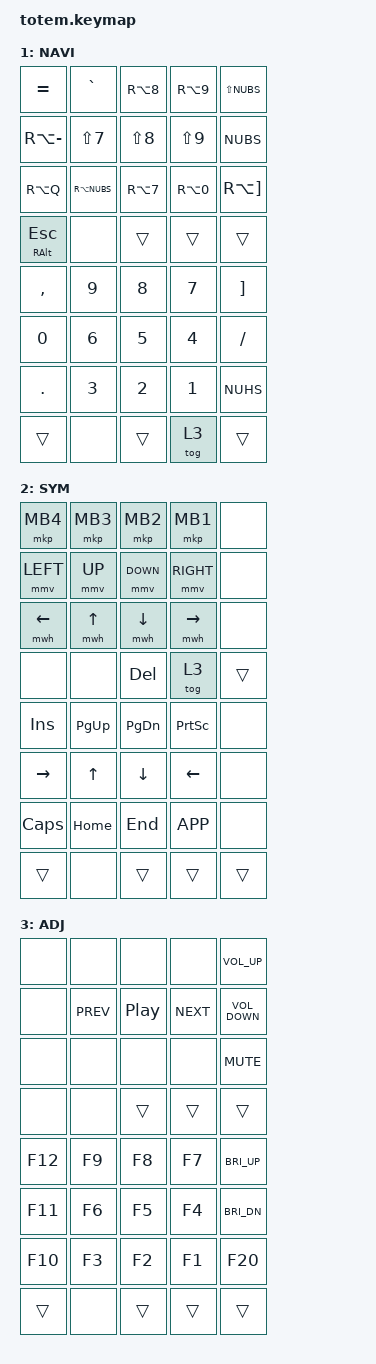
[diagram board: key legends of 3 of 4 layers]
//
//                                                        ▀▀▀▀▀     ▀▀▀▀▀          ▀▀█▀▀
//                                                        ▄▀▀▀▄  ▄  ▄▀▀▀▄  ▄  ▄▀▀▀▄  █  ▄▀▀▀▄
//                                                        █   █  █  █   █  █  █   █  █  █   █
//                                                         ▀▀▀   █   ▀▀▀   █   ▀▀▀   ▀   ▀▀▀
//                                                               █      ▄▄▄█▄▄▄    █   █
//                                                               ▀      █  █  █     █▄█
//                                                             ▀▀▀▀▀    █  █  █      ▀
//                                                                      ▀  ▀  ▀
//
// ▄▄▄▄▄▄▄▄▄▄▄▄▄▄▄▄▄▄▄▄▄▄▄▄▄▄▄▄▄▄▄▄▄▄▄▄▄▄▄▄▄▄▄▄▄▄▄▄▄▄▄▄▄▄▄▄▄▄▄▄▄▄▄▄▄▄▄▄▄▄▄▄▄▄▄▄▄▄▄▄▄▄▄▄▄▄▄▄▄▄▄▄▄▄▄▄▄▄▄▄▄▄▄▄▄▄▄▄▄▄▄▄▄▄▄▄▄▄▄▄▄▄▄▄▄▄▄▄▄▄▄▄▄▄▄▄▄▄▄▄▄▄▄▄▄▄▄▄▄


#include <behaviors.dtsi>
#include <dt-bindings/zmk/keys.h>
#include <dt-bindings/zmk/bt.h>
#include <dt-bindings/zmk/outputs.h>

#define BASE 0
#define NAV  1
#define SYM  2
#define ADJ  3

&mt {
  quick-tap-ms = <100>;
  global-quick-tap;
  flavor = "tap-preferred";
  tapping-term-ms = <170>;
};

/ {
    // combos {
    //         compatible = "zmk,combos";
    //         combo_esc {
    //             timeout-ms = <50>;
    //             key-positions = <0 1>;
    //             bindings = <&kp ESC>;
    //         };
    // };
combos {
        compatible = "zmk,combos";

        combo0 {
            timeout-ms = <40>;
            key-positions = <10 11 12 13>;
            bindings = <&kp LC(LALT)>;
        };

        combo1 {
            timeout-ms = <40>;
            key-positions = <33 32 31 30>;
            bindings = <&kp LC(LALT)>;
        };

        combo2 {
            timeout-ms = <40>;
            key-positions = <11 12 13>;
            bindings = <&kp LA(LGUI)>;
        };

        combo3 {
            timeout-ms = <40>;
            key-positions = <32 31 30>;
            bindings = <&kp LA(LGUI)>;
        };

        combo4 {
            timeout-ms = <40>;
            key-positions = <11 12 13>;
            bindings = <&kp LC(LGUI)>;
        };

        combo5 {
            timeout-ms = <40>;
            key-positions = <32 31 30>;
            bindings = <&kp LC(LGUI)>;
        };

        combo6 {
            timeout-ms = <40>;
            key-positions = <5 7 8 6>;
            bindings = <&kp LC(C)>;
        };

        combo7 {
            timeout-ms = <40>;
            key-positions = <28 27 26 25>;
            bindings = <&kp LC(C)>;
        };

        combo8 {
            timeout-ms = <40>;
            key-positions = <0 1 2 3>;
            bindings = <&kp ESC>;
        };

        combo9 {
            timeout-ms = <40>;
            key-positions = <23 22 21 20>;
            bindings = <&kp ESC>;
        };

        combo10 {
            timeout-ms = <40>;
            key-positions = <12 13 19>;
            bindings = <&kp LC(LSHIFT)>;
        };

        combo11 {
            timeout-ms = <40>;
            key-positions = <33 32 19>;
            bindings = <&none>;
        };

        combo12 {
            timeout-ms = <40>;
            key-positions = <11 12>;
            bindings = <&kp LALT>;
        };

        combo13 {
            timeout-ms = <40>;
            key-positions = <32 31>;
            bindings = <&kp LALT>;
        };

        combo14 {
            timeout-ms = <40>;
            key-positions = <11 12>;
            bindings = <&kp LGUI>;
        };

        combo15 {
            timeout-ms = <40>;
            key-positions = <32 31>;
            bindings = <&kp LGUI>;
        };

        combo16 {
            timeout-ms = <40>;
            key-positions = <12 13>;
            bindings = <&kp LCTRL>;
        };

        combo17 {
            timeout-ms = <40>;
            key-positions = <33 32>;
            bindings = <&kp LCTRL>;
        };

        combo18 {
            timeout-ms = <40>;
            key-positions = <11 31>;
            bindings = <&kp TAB>;
        };

        combo19 {
            timeout-ms = <40>;
            key-positions = <10 30>;
            bindings = <&kp ESC>;
        };

        combo20 {
            timeout-ms = <40>;
            key-positions = <0 0>;
            bindings = <&kp LCTRL>;
        };

        combo21 {
            timeout-ms = <40>;
            key-positions = <0 0>;
            bindings = <&kp LCTRL>;
        };

        combo22 {
            timeout-ms = <40>;
            key-positions = <0 0 0>;
            bindings = <&kp LC(LGUI)>;
        };

        combo23 {
            timeout-ms = <40>;
            key-positions = <0 0 0>;
            bindings = <&kp LA(LGUI)>;
        };

        combo24 {
            timeout-ms = <40>;
            key-positions = <0 0>;
            bindings = <&kp LGUI>;
        };

        combo25 {
            timeout-ms = <40>;
            key-positions = <0 0 0 0>;
            bindings = <&kp LC(LALT)>;
        };

        combo26 {
            timeout-ms = <40>;
            key-positions = <33 32 19>;
            bindings = <&kp LC(LSHIFT)>;
        };

        combo27 {
            timeout-ms = <40>;
            key-positions = <11 12 13 19>;
            bindings = <&kp LC(LSHIFT)>;
        };
    };

    macros {
        gif: gif {
            label = "giphy";
            compatible = "zmk,behavior-macro";
            #binding-cells = <0>;
            bindings
                = <&macro_press &kp LSHFT>
                , <&macro_tap &kp N2>
                , <&macro_release &kp LSHFT>
                , <&macro_tap &kp G &kp I &kp F>
                ;
        };
    };

        keymap {
                compatible = "zmk,keymap";
// ▄▄▄▄▄▄▄▄▄▄▄▄▄▄▄▄▄▄▄▄▄▄▄▄▄▄▄▄▄▄▄▄▄▄▄▄▄▄▄▄▄▄▄▄▄▄▄▄▄▄▄▄▄▄▄▄▄▄▄▄▄▄▄▄▄▄▄▄▄▄▄▄▄▄▄▄▄▄▄▄▄▄▄▄▄▄▄▄▄▄▄▄▄▄▄▄▄▄▄▄▄▄▄▄▄▄▄▄▄▄▄▄▄▄▄▄▄▄▄▄▄▄▄▄▄▄▄▄▄▄▄▄▄▄▄▄▄▄▄▄▄▄▄▄▄▄▄▄▄

                base_layer {
// ┏━━━━━━━━━━━━━━━━━━━━━━━━━━━━━━━━━━━━━━━┓
label= "BASE"                              ;
// ┗━━━━━━━━━━━━━━━━━━━━━━━━━━━━━━━━━━━━━━━┛
//             ┏━━━━━━━━━━━┳━━━━━━━━━━━┳━━━━━━━━━━━┳━━━━━━━━━━━┳━━━━━━━━━━━┓   ┏━━━━━━━━━━━┳━━━━━━━━━━━┳━━━━━━━━━━━┳━━━━━━━━━━━┳━━━━━━━━━━━┓
//             ┃     Q     ┃     W     ┃     F     ┃     P     ┃     G     ┃   ┃     J     ┃     L     ┃     U     ┃     Y     ┃     ;     ┃
//             ┣━━━━━━━━━━━╋━━━━━━━━━━━╋━━━━━━━━━━━╋━━━━━━━━━━━╋━━━━━━━━━━━┫   ┣━━━━━━━━━━━╋━━━━━━━━━━━╋━━━━━━━━━━━╋━━━━━━━━━━━╋━━━━━━━━━━━┫
//             ┃     A     ┃     R     ┃     S     ┃     T     ┃     D     ┃   ┃     H     ┃     N     ┃     E     ┃     I     ┃     O     ┃
// ┏━━━━━━━━━━━╋━━━━━━━━━━━╋━━━━━━━━━━━╋━━━━━━━━━━━╋━━━━━━━━━━━╋━━━━━━━━━━━┫   ┣━━━━━━━━━━━╋━━━━━━━━━━━╋━━━━━━━━━━━╋━━━━━━━━━━━╋━━━━━━━━━━━╋━━━━━━━━━━━┓
// ┃           ┃     Z     ┃     X     ┃     C     ┃     V     ┃     B     ┃   ┃     K     ┃     M     ┃     ,     ┃     .     ┃     /     ┃           ┃
// ┗━━━━━━━━━━━┻━━━━━━━━━━━┻━━━━━━━━━━━╋━━━━━━━━━━━╋━━━━━━━━━━━╋━━━━━━━━━━━┫   ┣━━━━━━━━━━━╋━━━━━━━━━━━╋━━━━━━━━━━━╋━━━━━━━━━━━┻━━━━━━━━━━━┻━━━━━━━━━━━┛
//                                     ┃           ┃    TAB    ┃    SPC    ┃   ┃   ENTER   ┃   BSPC    ┃           ┃
//                                     ┗━━━━━━━━━━━┻━━━━━━━━━━━┻━━━━━━━━━━━┛   ┗━━━━━━━━━━━┻━━━━━━━━━━━┻━━━━━━━━━━━┛
//  bindings = <
// // ╷           ╷           ╷           ╷           ╷           ╷           ╷   ╷           ╷           ╷           ╷           ╷           ╷           ╷
//
//                 &kp Q       &kp W       &kp F       &kp P       &kp G           &kp J       &kp L       &kp U       &kp Y       &kp SEMI
//                 &mt LGUI A  &mt LALT R  &mt LCTRL S &mt LSHFT T &kp D           &kp H       &mt RSHFT N &mt RCTRL E &mt RALT I  &mt RGUI O
//     &kp Z       &kp Z       &kp X       &kp C       &kp V       &kp B           &kp K       &kp M       &kp COMMA   &kp DOT     &kp FSLH    &kp FSLH
//                                         &kp TAB     &kp TAB     &lt NAV SPACE   &lt SYM RET &kp BSPC    &kp BSPC
//                         >;
bindings = <
            &kp Z &kp Y &kp U    &kp A  &kp Q     &kp P  &kp B  &kp M  &kp L  &kp SQT
            &kp C &kp S &kp I    &kp E  &kp O     &kp D  &kp T  &kp N  &kp R  &kp H
    &kp TAB &kp V &kp X &kp LBKT &kp SEMI &kp RBKT &kp W &kp G &kp F &kp J &kp K &kp DOT
                     &kp BSPC &tog 1 &kp LSHIFT &kp SPACE &tog 2 &kp ENTER
>;
                };

// ▄▄▄▄▄▄▄▄▄▄▄▄▄▄▄▄▄▄▄▄▄▄▄▄▄▄▄▄▄▄▄▄▄▄▄▄▄▄▄▄▄▄▄▄▄▄▄▄▄▄▄▄▄▄▄▄▄▄▄▄▄▄▄▄▄▄▄▄▄▄▄▄▄▄▄▄▄▄▄▄▄▄▄▄▄▄▄▄▄▄▄▄▄▄▄▄▄▄▄▄▄▄▄▄▄▄▄▄▄▄▄▄▄▄▄▄▄▄▄▄▄▄▄▄▄▄▄▄▄▄▄▄▄▄▄▄▄▄▄▄▄▄▄▄▄▄▄▄▄


                nav_layer {
// ┏━━━━━━━━━━━━━━━━━━━━━━━━━━━━━━━━━━━━━━━┓
label= "NAVI"                              ;
// ┗━━━━━━━━━━━━━━━━━━━━━━━━━━━━━━━━━━━━━━━┛
//             ┏━━━━━━━━━━━┳━━━━━━━━━━━┳━━━━━━━━━━━┳━━━━━━━━━━━┳━━━━━━━━━━━┓   ┏━━━━━━━━━━━┳━━━━━━━━━━━┳━━━━━━━━━━━┳━━━━━━━━━━━┳━━━━━━━━━━━┓
//             ┃           ┃           ┃     UP    ┃           ┃     {     ┃   ┃     }     ┃     7     ┃     8     ┃     9     ┃     +     ┃
//             ┣━━━━━━━━━━━╋━━━━━━━━━━━╋━━━━━━━━━━━╋━━━━━━━━━━━╋━━━━━━━━━━━┫   ┣━━━━━━━━━━━╋━━━━━━━━━━━╋━━━━━━━━━━━╋━━━━━━━━━━━╋━━━━━━━━━━━┫
//             ┃   SHIFT   ┃   LEFT    ┃    DOWN   ┃   RIGHT   ┃     [     ┃   ┃     ]     ┃     4     ┃     5     ┃     6     ┃     -     ┃
// ┏━━━━━━━━━━━╋━━━━━━━━━━━╋━━━━━━━━━━━╋━━━━━━━━━━━╋━━━━━━━━━━━╋━━━━━━━━━━━┫   ┣━━━━━━━━━━━╋━━━━━━━━━━━╋━━━━━━━━━━━╋━━━━━━━━━━━╋━━━━━━━━━━━╋━━━━━━━━━━━┓
// ┃           ┃           ┃   P UP    ┃  C LOCK   ┃  P DOWN   ┃     (     ┃   ┃     )     ┃     1     ┃     2     ┃     3     ┃     *     ┃           ┃
// ┗━━━━━━━━━━━┻━━━━━━━━━━━┻━━━━━━━━━━━╋━━━━━━━━━━━╋━━━━━━━━━━━╋━━━━━━━━━━━┫   ┣━━━━━━━━━━━╋━━━━━━━━━━━╋━━━━━━━━━━━╋━━━━━━━━━━━┻━━━━━━━━━━━┻━━━━━━━━━━━┛
//                                     ┃           ┃    TAB    ┃    SPC    ┃   ┃    DEL    ┃     0     ┃           ┃
//                                     ┗━━━━━━━━━━━┻━━━━━━━━━━━┻━━━━━━━━━━━┛   ┗━━━━━━━━━━━┻━━━━━━━━━━━┻━━━━━━━━━━━┛
//  bindings = <
// // ╷           ╷           ╷           ╷           ╷           ╷           ╷   ╷           ╷           ╷           ╷           ╷           ╷           ╷
//
//                 &kp ESC     &bt BT_CLR  &kp UP      &kp EQUAL   &kp LBRC        &kp RBRC    &kp KP_N7   &kp KP_N8   &kp KP_N9   &kp KP_PLUS
//                 &kp LSHFT   &kp LEFT    &kp DOWN    &kp RIGHT   &kp LBKT        &kp RBKT    &kp KP_N4   &kp KP_N5   &kp KP_N6   &kp KP_MINUS
//     &trans      &kp DEL     &kp PG_UP   &kp CAPS    &kp PG_DN   &kp LPAR        &kp RPAR    &kp KP_N1   &kp KP_N2   &kp KP_N3   &kp KP_MULTIPLY &trans
//                                         &trans      &trans      &trans          &mo ADJ     &kp KP_N0   &trans
//                         >;
   bindings = <
                &kp EQUAL &kp GRAVE &kp RA(8) &kp RA(9) &kp LS(NUBS)
                &kp RA(MINUS) &kp LS(7) &kp LS(8) &kp LS(9) &kp NUBS
                &kp RA(Q) &kp RA(NUBS) &kp RA(7) &kp RA(0) &kp RA(RBKT)
                &mt RALT ESC &none &trans &trans &trans
                &kp COMMA &kp 9 &kp 8 &kp 7 &kp RBKT
                &kp 0 &kp 6 &kp 5 &kp 4 &kp SLASH
                &kp DOT &kp 3 &kp 2 &kp 1 &kp NUHS
                &trans &none &trans &tog 3 &trans
            >;
                };

// ▄▄▄▄▄▄▄▄▄▄▄▄▄▄▄▄▄▄▄▄▄▄▄▄▄▄▄▄▄▄▄▄▄▄▄▄▄▄▄▄▄▄▄▄▄▄▄▄▄▄▄▄▄▄▄▄▄▄▄▄▄▄▄▄▄▄▄▄▄▄▄▄▄▄▄▄▄▄▄▄▄▄▄▄▄▄▄▄▄▄▄▄▄▄▄▄▄▄▄▄▄▄▄▄▄▄▄▄▄▄▄▄▄▄▄▄▄▄▄▄▄▄▄▄▄▄▄▄▄▄▄▄▄▄▄▄▄▄▄▄▄▄▄▄▄▄▄▄▄


                sim_layer {
// ┏━━━━━━━━━━━━━━━━━━━━━━━━━━━━━━━━━━━━━━━┓
label= "SYM"                               ;
// ┗━━━━━━━━━━━━━━━━━━━━━━━━━━━━━━━━━━━━━━━┛
//             ┏━━━━━━━━━━━┳━━━━━━━━━━━┳━━━━━━━━━━━┳━━━━━━━━━━━┳━━━━━━━━━━━┓   ┏━━━━━━━━━━━┳━━━━━━━━━━━┳━━━━━━━━━━━┳━━━━━━━━━━━┳━━━━━━━━━━━┓
//             ┃     !     ┃     @     ┃     #     ┃     $     ┃     %     ┃   ┃     ˆ     ┃     &     ┃     Ü     ┃     '     ┃     "     ┃
//             ┣━━━━━━━━━━━╋━━━━━━━━━━━╋━━━━━━━━━━━╋━━━━━━━━━━━╋━━━━━━━━━━━┫   ┣━━━━━━━━━━━╋━━━━━━━━━━━╋━━━━━━━━━━━╋━━━━━━━━━━━╋━━━━━━━━━━━┫
//             ┃     Ä     ┃           ┃    SZ     ┃           ┃           ┃   ┃   MUTE    ┃   YEN     ┃   EURO    ┃  POUND    ┃     Ö     ┃
// ┏━━━━━━━━━━━╋━━━━━━━━━━━╋━━━━━━━━━━━╋━━━━━━━━━━━╋━━━━━━━━━━━╋━━━━━━━━━━━┫   ┣━━━━━━━━━━━╋━━━━━━━━━━━╋━━━━━━━━━━━╋━━━━━━━━━━━╋━━━━━━━━━━━╋━━━━━━━━━━━┓
// ┃           ┃  EMAIL1   ┃  EMAIL2   ┃           ┃           ┃           ┃   ┃   VOL-    ┃   VOL+    ┃   LAST    ┃   NEXT    ┃     \     ┃           ┃
// ┗━━━━━━━━━━━┻━━━━━━━━━━━┻━━━━━━━━━━━╋━━━━━━━━━━━╋━━━━━━━━━━━╋━━━━━━━━━━━┫   ┣━━━━━━━━━━━╋━━━━━━━━━━━╋━━━━━━━━━━━╋━━━━━━━━━━━┻━━━━━━━━━━━┻━━━━━━━━━━━┛
//                                     ┃           ┃    GIF    ┃    ADJ    ┃   ┃           ┃           ┃           ┃
//                                     ┗━━━━━━━━━━━┻━━━━━━━━━━━┻━━━━━━━━━━━┛   ┗━━━━━━━━━━━┻━━━━━━━━━━━┻━━━━━━━━━━━┛
//  bindings = <
// // ╷           ╷           ╷           ╷           ╷           ╷           ╷   ╷           ╷           ╷           ╷           ╷           ╷           ╷
//
//                 &kp EXCL    &kp AT      &kp HASH    &kp DLLR    &kp PRCNT       &kp CARET   &kp AMPS    &kp RA(U)   &kp SQT     &kp DQT
//                 &kp RA(A)   &trans      &kp RA(S)   &trans      &trans          &kp C_MUTE  &kp LS(RA(N4)) &kp RA(N5) &kp RA(N4)   &kp RA(O)
//     &trans      &kp RA(F18) &kp RA(F19) &trans      &trans      &trans          &kp C_VOL_DN &kp C_VOL_UP &kp C_PREV &kp C_NEXT  &kp BSLH   &trans
//                                         &trans      &gif        &mo ADJ         &trans      &kp C_PP    &trans
//                         >;
  bindings = <
                &mkp MB4 &mkp MB3 &mkp MB2 &mkp MB1 &none
                &mmv LEFT &mmv UP &mmv DOWN &mmv RIGHT &none
                &mwh LEFT &mwh UP &mwh DOWN &mwh RIGHT &none
                &none &none &kp DELETE &tog 3 &trans
                &kp INSERT &kp PG_UP &kp PG_DN &kp PSCRN &none
                &kp RIGHT &kp UP &kp DOWN &kp LEFT &none
                &kp CAPS &kp HOME &kp END &kp APP &none
                &trans &none &trans &trans &trans
            >;
                };

// ▄▄▄▄▄▄▄▄▄▄▄▄▄▄▄▄▄▄▄▄▄▄▄▄▄▄▄▄▄▄▄▄▄▄▄▄▄▄▄▄▄▄▄▄▄▄▄▄▄▄▄▄▄▄▄▄▄▄▄▄▄▄▄▄▄▄▄▄▄▄▄▄▄▄▄▄▄▄▄▄▄▄▄▄▄▄▄▄▄▄▄▄▄▄▄▄▄▄▄▄▄▄▄▄▄▄▄▄▄▄▄▄▄▄▄▄▄▄▄▄▄▄▄▄▄▄▄▄▄▄▄▄▄▄▄▄▄▄▄▄▄▄▄▄▄▄▄▄▄


                adjust_layer {
// ┏━━━━━━━━━━━━━━━━━━━━━━━━━━━━━━━━━━━━━━━┓
label= "ADJ"                               ;
// ┗━━━━━━━━━━━━━━━━━━━━━━━━━━━━━━━━━━━━━━━┛
//             ┏━━━━━━━━━━━┳━━━━━━━━━━━┳━━━━━━━━━━━┳━━━━━━━━━━━┳━━━━━━━━━━━┓   ┏━━━━━━━━━━━┳━━━━━━━━━━━┳━━━━━━━━━━━┳━━━━━━━━━━━┳━━━━━━━━━━━┓
//             ┃   RESET   ┃ BT CLEAR  ┃  OUT TOG  ┃           ┃           ┃   ┃           ┃    F7     ┃    F8     ┃    F9     ┃    F12    ┃
//             ┣━━━━━━━━━━━╋━━━━━━━━━━━╋━━━━━━━━━━━╋━━━━━━━━━━━╋━━━━━━━━━━━┫   ┣━━━━━━━━━━━╋━━━━━━━━━━━╋━━━━━━━━━━━╋━━━━━━━━━━━╋━━━━━━━━━━━┫
//             ┃ BOOTLOAD  ┃ BT NEXT   ┃           ┃           ┃           ┃   ┃           ┃    F4     ┃    F5     ┃    F6     ┃    F11    ┃
// ┏━━━━━━━━━━━╋━━━━━━━━━━━╋━━━━━━━━━━━╋━━━━━━━━━━━╋━━━━━━━━━━━╋━━━━━━━━━━━┫   ┣━━━━━━━━━━━╋━━━━━━━━━━━╋━━━━━━━━━━━╋━━━━━━━━━━━╋━━━━━━━━━━━╋━━━━━━━━━━━┓
// ┃           ┃           ┃ BT PREV   ┃           ┃           ┃           ┃   ┃           ┃    F1     ┃    F2     ┃    F3     ┃    F10    ┃           ┃
// ┗━━━━━━━━━━━┻━━━━━━━━━━━┻━━━━━━━━━━━╋━━━━━━━━━━━╋━━━━━━━━━━━╋━━━━━━━━━━━┫   ┣━━━━━━━━━━━╋━━━━━━━━━━━╋━━━━━━━━━━━╋━━━━━━━━━━━┻━━━━━━━━━━━┻━━━━━━━━━━━┛
//                                     ┃           ┃           ┃           ┃   ┃           ┃           ┃           ┃
//                                     ┗━━━━━━━━━━━┻━━━━━━━━━━━┻━━━━━━━━━━━┛   ┗━━━━━━━━━━━┻━━━━━━━━━━━┻━━━━━━━━━━━┛
//  bindings = <
// // ╷           ╷           ╷           ╷           ╷           ╷           ╷   ╷           ╷           ╷           ╷           ╷           ╷           ╷
//
//                 &sys_reset  &bt BT_CLR &out OUT_TOG &trans      &trans          &trans      &kp F7      &kp F8      &kp F9      &kp F12
//                 &bootloader &bt BT_NXT  &trans      &trans      &trans          &trans      &kp F4      &kp F5      &kp F6      &kp F11
//     &trans      &trans      &bt BT_PRV  &trans      &trans      &trans          &trans      &kp F1      &kp F2      &kp F3      &kp F10     &trans
//                                         &trans      &trans      &trans          &trans      &trans      &trans
//                         >;
 bindings = <
                &none &none &none &none &kp VOL_UP
                &none &kp C_PREV &kp C_PLAY_PAUSE &kp C_NEXT &kp VOL_DOWN
                &none &none &none &none &kp MUTE
                &none &none &trans &trans &trans
                &kp F12 &kp F9 &kp F8 &kp F7 &kp C_BRI_UP
                &kp F11 &kp F6 &kp F5 &kp F4 &kp C_BRI_DN
                &kp F10 &kp F3 &kp F2 &kp F1 &kp F20
                &trans &none &trans &trans &trans
            >;
                };
        };
};
